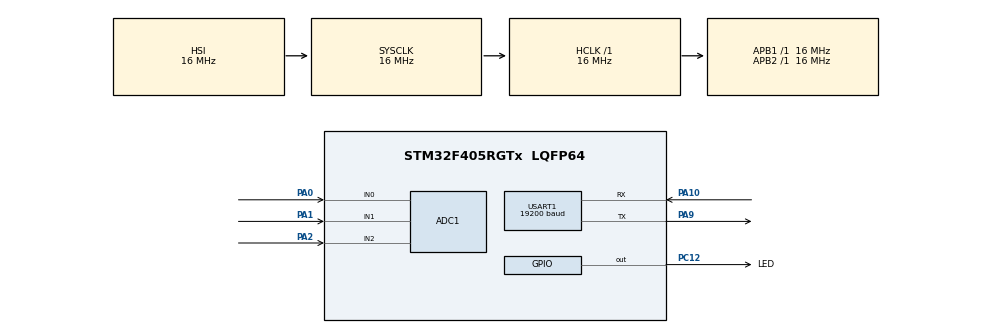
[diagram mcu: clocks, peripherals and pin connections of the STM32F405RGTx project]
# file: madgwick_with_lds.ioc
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ADC1.Channel-0\#ChannelRegularConversion=ADC_CHANNEL_0
ADC1.Channel-1\#ChannelRegularConversion=ADC_CHANNEL_1
ADC1.Channel-2\#ChannelRegularConversion=ADC_CHANNEL_2
ADC1.ClockPrescaler=ADC_CLOCK_SYNC_PCLK_DIV8
ADC1.NbrOfConversion=3
ADC1.NbrOfConversionFlag=1
ADC1.Rank-0\#ChannelRegularConversion=1
ADC1.Rank-1\#ChannelRegularConversion=2
ADC1.Rank-2\#ChannelRegularConversion=3
ADC1.SamplingTime-0\#ChannelRegularConversion=ADC_SAMPLETIME_480CYCLES
ADC1.SamplingTime-1\#ChannelRegularConversion=ADC_SAMPLETIME_480CYCLES
ADC1.SamplingTime-2\#ChannelRegularConversion=ADC_SAMPLETIME_480CYCLES
ADC1.master=1
Mcu.Family=STM32F4
Mcu.Name=STM32F405RGTx
Mcu.Package=LQFP64
NVIC.PriorityGroup=NVIC_PRIORITYGROUP_4
PA0-WKUP.Signal=ADCx_IN0
PA1.Signal=ADCx_IN1
PA10.Mode=Asynchronous
PA10.Signal=USART1_RX
PA2.Signal=ADCx_IN2
PA9.Mode=Asynchronous
PA9.Signal=USART1_TX
PC12.GPIO_Label=LED
PC12.GPIO_ModeDefaultOutputPP=GPIO_MODE_OUTPUT_OD
PC12.GPIO_PuPd=GPIO_PULLUP
PC12.PinState=GPIO_PIN_SET
PC12.Signal=GPIO_Output
ProjectManager.HeapSize=0x200
ProjectManager.StackSize=0x400
ProjectManager.TargetToolchain=STM32CubeIDE
RCC.AHBFreq_Value=16000000
RCC.APB1Freq_Value=16000000
RCC.APB2Freq_Value=16000000
RCC.CortexFreq_Value=16000000
RCC.HSE_VALUE=25000000
RCC.HSI_VALUE=16000000
RCC.LSE_VALUE=32768
RCC.SYSCLKFreq_VALUE=16000000
RCC.VCOOutputFreq_Value=192000000
SH.ADCx_IN0.0=ADC1_IN0,IN0
SH.ADCx_IN1.0=ADC1_IN1,IN1
SH.ADCx_IN2.0=ADC1_IN2,IN2
USART1.BaudRate=19200
USART1.VirtualMode=VM_ASYNC
board=custom

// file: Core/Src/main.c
/* USER CODE BEGIN Header */
/**
  ******************************************************************************
  * @file           : main.c
  * @brief          : Main program body
  ******************************************************************************
  * @attention
  *
  * <h2><center>&copy; Copyright (c) 2021 STMicroelectronics.
  * All rights reserved.</center></h2>
  *
  * This software component is licensed by ST under BSD 3-Clause license,
  * the "License"; You may not use this file except in compliance with the
  * License. You may obtain a copy of the License at:
  *                        opensource.org/licenses/BSD-3-Clause
  *
  ******************************************************************************
  */
/* USER CODE END Header */
#include "main.h"

ADC_HandleTypeDef hadc1;

UART_HandleTypeDef huart1;

void SystemClock_Config(void);
static void MX_GPIO_Init(void);
static void MX_USART1_UART_Init(void);
static void MX_ADC1_Init(void);
/* USER CODE BEGIN PFP */
int tmain();

/* USER CODE END PFP */

int main(void)
{

  /* MCU Configuration--------------------------------------------------------*/

  /* Reset of all peripherals, Initializes the Flash interface and the Systick. */
  HAL_Init();

  /* Configure the system clock */
  SystemClock_Config();

  /* Initialize all configured peripherals */
  MX_GPIO_Init();
  MX_USART1_UART_Init();
  MX_ADC1_Init();

  /* Infinite loop */
  /* USER CODE BEGIN WHILE */
  return tmain();
  while (1)
  {
    /* USER CODE END WHILE */

  }
}

void SystemClock_Config(void)
{
  RCC_OscInitTypeDef RCC_OscInitStruct = {0};
  RCC_ClkInitTypeDef RCC_ClkInitStruct = {0};

  /** Configure the main internal regulator output voltage
  */
  __HAL_RCC_PWR_CLK_ENABLE();
  __HAL_PWR_VOLTAGESCALING_CONFIG(PWR_REGULATOR_VOLTAGE_SCALE1);
  /** Initializes the RCC Oscillators according to the specified parameters
  * in the RCC_OscInitTypeDef structure.
  */
  RCC_OscInitStruct.OscillatorType = RCC_OSCILLATORTYPE_HSI;
  RCC_OscInitStruct.HSIState = RCC_HSI_ON;
  RCC_OscInitStruct.HSICalibrationValue = RCC_HSICALIBRATION_DEFAULT;
  RCC_OscInitStruct.PLL.PLLState = RCC_PLL_NONE;
  if (HAL_RCC_OscConfig(&RCC_OscInitStruct) != HAL_OK)
  {
    Error_Handler();
  }
  /** Initializes the CPU, AHB and APB buses clocks
  */
  RCC_ClkInitStruct.ClockType = RCC_CLOCKTYPE_HCLK|RCC_CLOCKTYPE_SYSCLK
                              |RCC_CLOCKTYPE_PCLK1|RCC_CLOCKTYPE_PCLK2;
  RCC_ClkInitStruct.SYSCLKSource = RCC_SYSCLKSOURCE_HSI;
  RCC_ClkInitStruct.AHBCLKDivider = RCC_SYSCLK_DIV1;
  RCC_ClkInitStruct.APB1CLKDivider = RCC_HCLK_DIV1;
  RCC_ClkInitStruct.APB2CLKDivider = RCC_HCLK_DIV1;

  if (HAL_RCC_ClockConfig(&RCC_ClkInitStruct, FLASH_LATENCY_0) != HAL_OK)
  {
    Error_Handler();
  }
}

static void MX_ADC1_Init(void)
{

  ADC_ChannelConfTypeDef sConfig = {0};

  /** Configure the global features of the ADC (Clock, Resolution, Data Alignment and number of conversion)
  */
  hadc1.Instance = ADC1;
  hadc1.Init.ClockPrescaler = ADC_CLOCK_SYNC_PCLK_DIV8;
  hadc1.Init.Resolution = ADC_RESOLUTION_12B;
  hadc1.Init.ScanConvMode = ENABLE;
  hadc1.Init.ContinuousConvMode = DISABLE;
  hadc1.Init.DiscontinuousConvMode = DISABLE;
  hadc1.Init.ExternalTrigConvEdge = ADC_EXTERNALTRIGCONVEDGE_NONE;
  hadc1.Init.ExternalTrigConv = ADC_SOFTWARE_START;
  hadc1.Init.DataAlign = ADC_DATAALIGN_RIGHT;
  hadc1.Init.NbrOfConversion = 3;
  hadc1.Init.DMAContinuousRequests = DISABLE;
  hadc1.Init.EOCSelection = ADC_EOC_SINGLE_CONV;
  if (HAL_ADC_Init(&hadc1) != HAL_OK)
  {
    Error_Handler();
  }
  /** Configure for the selected ADC regular channel its corresponding rank in the sequencer and its sample time.
  */
  sConfig.Channel = ADC_CHANNEL_0;
  sConfig.Rank = 1;
  sConfig.SamplingTime = ADC_SAMPLETIME_480CYCLES;
  if (HAL_ADC_ConfigChannel(&hadc1, &sConfig) != HAL_OK)
  {
    Error_Handler();
  }
  /** Configure for the selected ADC regular channel its corresponding rank in the sequencer and its sample time.
  */
  sConfig.Channel = ADC_CHANNEL_1;
  sConfig.Rank = 2;
  if (HAL_ADC_ConfigChannel(&hadc1, &sConfig) != HAL_OK)
  {
    Error_Handler();
  }
  /** Configure for the selected ADC regular channel its corresponding rank in the sequencer and its sample time.
  */
  sConfig.Channel = ADC_CHANNEL_2;
  sConfig.Rank = 3;
  if (HAL_ADC_ConfigChannel(&hadc1, &sConfig) != HAL_OK)
  {
    Error_Handler();
  }

}

static void MX_USART1_UART_Init(void)
{

  huart1.Instance = USART1;
  huart1.Init.BaudRate = 19200;
  huart1.Init.WordLength = UART_WORDLENGTH_8B;
  huart1.Init.StopBits = UART_STOPBITS_1;
  huart1.Init.Parity = UART_PARITY_NONE;
  huart1.Init.Mode = UART_MODE_TX_RX;
  huart1.Init.HwFlowCtl = UART_HWCONTROL_NONE;
  huart1.Init.OverSampling = UART_OVERSAMPLING_16;
  if (HAL_UART_Init(&huart1) != HAL_OK)
  {
    Error_Handler();
  }

}

static void MX_GPIO_Init(void)
{
  GPIO_InitTypeDef GPIO_InitStruct = {0};

  /* GPIO Ports Clock Enable */
  __HAL_RCC_GPIOA_CLK_ENABLE();
  __HAL_RCC_GPIOC_CLK_ENABLE();

  /*Configure GPIO pin Output Level */
  HAL_GPIO_WritePin(LED_GPIO_Port, LED_Pin, GPIO_PIN_SET);

  /*Configure GPIO pin : LED_Pin */
  GPIO_InitStruct.Pin = LED_Pin;
  GPIO_InitStruct.Mode = GPIO_MODE_OUTPUT_OD;
  GPIO_InitStruct.Pull = GPIO_PULLUP;
  GPIO_InitStruct.Speed = GPIO_SPEED_FREQ_LOW;
  HAL_GPIO_Init(LED_GPIO_Port, &GPIO_InitStruct);

}

void Error_Handler(void)
{
}

/************************ (C) COPYRIGHT STMicroelectronics *****END OF FILE****/
